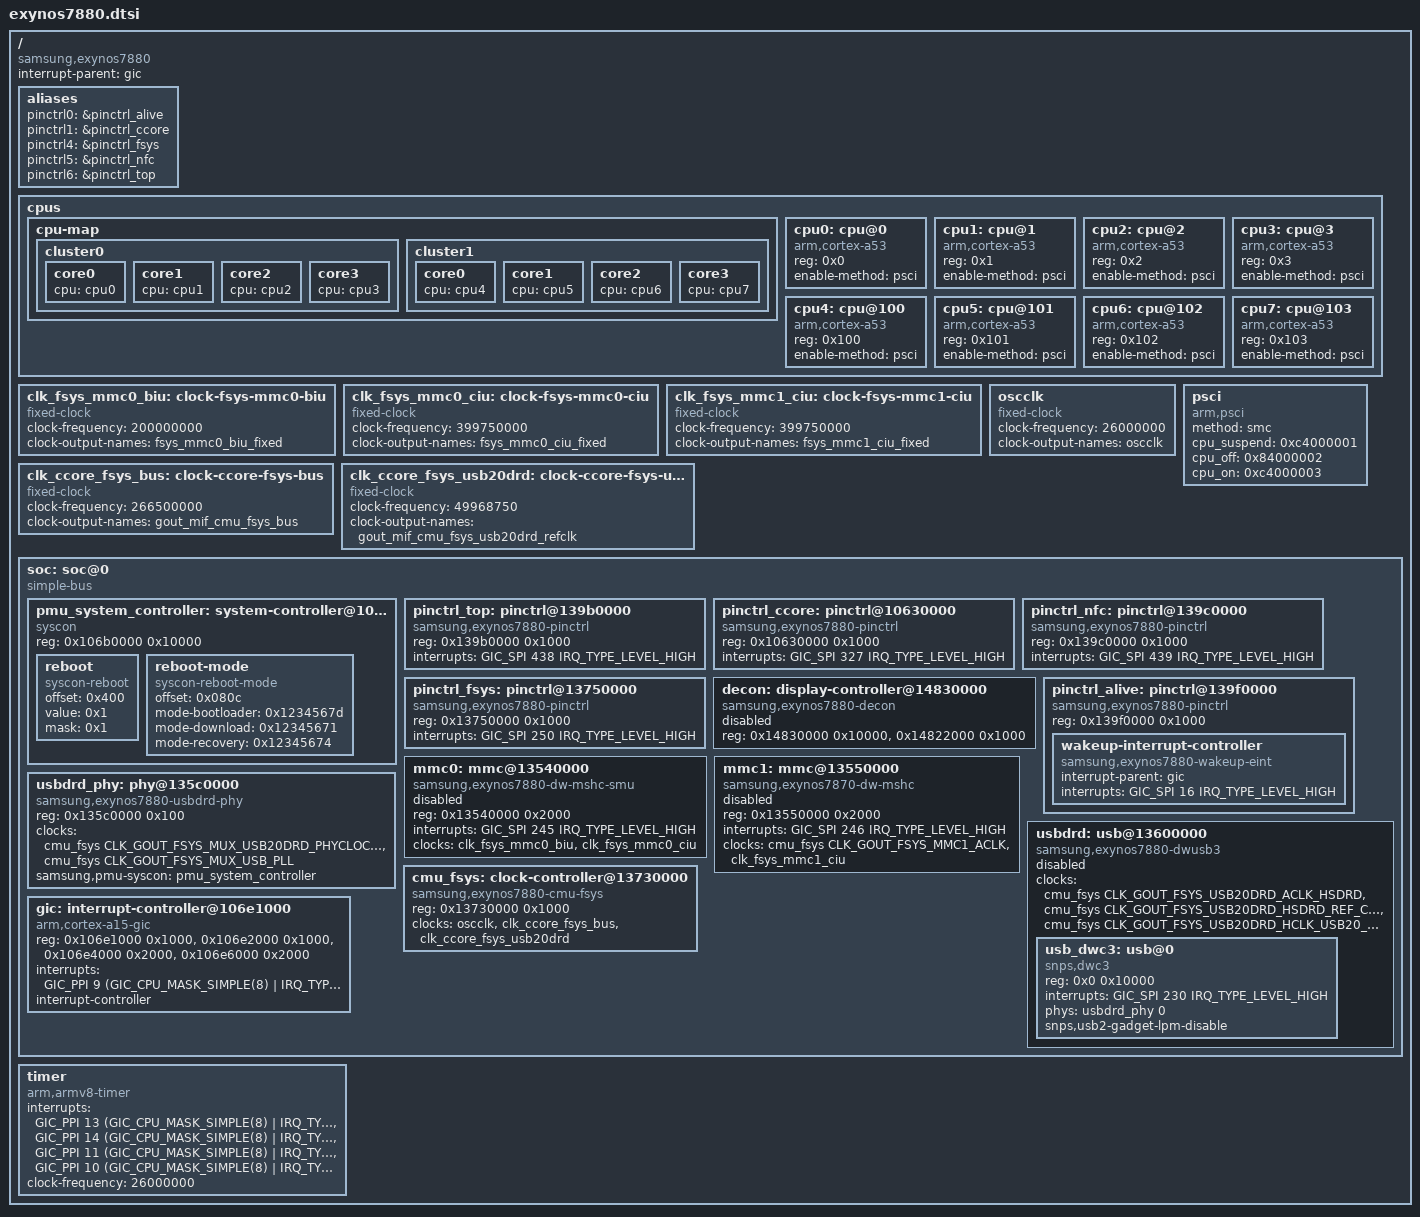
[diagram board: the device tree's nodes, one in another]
// SPDX-License-Identifier: GPL-2.0
/*
 * Samsung Exynos 7880 SoC device tree source
 *
 * M1: CPUs (PSCI), GIC, architected timer, PMU (reboot). M2: ALIVE pin
 * controller. M3: eMMC (fixed clocks). M4: CMU_FSYS (Exynos7870 driver,
 * identical register map), USB DRD PHY and DWC3 controller.
 *
 * Sources for every value:
 *  [D] Samsung universal7880 kernel, hybris-17.1: arch/arm64/boot/dts/exynos7880.dtsi
 *  [M] Linux v7.2 arch/arm64/boot/dts/exynos/exynos7870.dtsi (sibling SoC)
 *  [H] a5y17lte hardware readings, EVIDENCE.md sections 12
 *  [P] Samsung pwrcal S5E7880-cmusfr.h / -cmu.c / -pmusfr.h (same kernel)
 */

#include <dt-bindings/clock/samsung,exynos7870-cmu.h>
#include <dt-bindings/interrupt-controller/arm-gic.h>

/ {
	compatible = "samsung,exynos7880";
	#address-cells = <2>;
	#size-cells = <1>;

	interrupt-parent = <&gic>;

	aliases {
		/* index into exynos7880_pin_ctrl[] (Linux pinctrl-exynos-arm64.c) */
		pinctrl0 = &pinctrl_alive;
		pinctrl1 = &pinctrl_ccore;
		pinctrl4 = &pinctrl_fsys;
		pinctrl5 = &pinctrl_nfc;
		pinctrl6 = &pinctrl_top;
	};

	cpus {
		#address-cells = <1>;
		#size-cells = <0>;

		cpu-map {
			cluster0 {
				core0 { cpu = <&cpu0>; };
				core1 { cpu = <&cpu1>; };
				core2 { cpu = <&cpu2>; };
				core3 { cpu = <&cpu3>; };
			};

			cluster1 {
				core0 { cpu = <&cpu4>; };
				core1 { cpu = <&cpu5>; };
				core2 { cpu = <&cpu6>; };
				core3 { cpu = <&cpu7>; };
			};
		};

		/* [D] cpu@0..3, cpu@100..103, all cortex-a53, enable-method psci;
		 * [H] boot CPU MIDR 0x410fd034, MPIDR 0x80000000 */
		cpu0: cpu@0 {
			device_type = "cpu";
			compatible = "arm,cortex-a53";
			reg = <0x0>;
			enable-method = "psci";
		};

		cpu1: cpu@1 {
			device_type = "cpu";
			compatible = "arm,cortex-a53";
			reg = <0x1>;
			enable-method = "psci";
		};

		cpu2: cpu@2 {
			device_type = "cpu";
			compatible = "arm,cortex-a53";
			reg = <0x2>;
			enable-method = "psci";
		};

		cpu3: cpu@3 {
			device_type = "cpu";
			compatible = "arm,cortex-a53";
			reg = <0x3>;
			enable-method = "psci";
		};

		cpu4: cpu@100 {
			device_type = "cpu";
			compatible = "arm,cortex-a53";
			reg = <0x100>;
			enable-method = "psci";
		};

		cpu5: cpu@101 {
			device_type = "cpu";
			compatible = "arm,cortex-a53";
			reg = <0x101>;
			enable-method = "psci";
		};

		cpu6: cpu@102 {
			device_type = "cpu";
			compatible = "arm,cortex-a53";
			reg = <0x102>;
			enable-method = "psci";
		};

		cpu7: cpu@103 {
			device_type = "cpu";
			compatible = "arm,cortex-a53";
			reg = <0x103>;
			enable-method = "psci";
		};
	};

	/*
	 * TEMPORARY: there is no Exynos7880 clock driver yet, so the eMMC
	 * bus/card clocks are fixed clocks. S-Boot leaves them running.
	 * CIU measured on the phone (EVIDENCE.md 17b): CMU_CCORE MMC0 mux =
	 * BUS_PLL/2, div = 2, BUS_PLL = 26 MHz * 246 / 4 = 1599 MHz, so
	 * 1599 / 2 / 2 = 399.75 MHz. Replace with CMU clocks later.
	 */
	clk_fsys_mmc0_biu: clock-fsys-mmc0-biu {
		compatible = "fixed-clock";
		#clock-cells = <0>;
		clock-frequency = <200000000>;
		clock-output-names = "fsys_mmc0_biu_fixed";
	};

	clk_fsys_mmc0_ciu: clock-fsys-mmc0-ciu {
		compatible = "fixed-clock";
		#clock-cells = <0>;
		clock-frequency = <399750000>;
		clock-output-names = "fsys_mmc0_ciu_fixed";
	};

	/*
	 * mmc1 (SDIO, Wi-Fi): CIU clock from CMU_MIF CMU_FSYS_MMC1, which is not
	 * supported yet; same 399.75 MHz as the mmc0 stand-in (EVIDENCE 35: unverified
	 * for this block, S-Boot never uses mmc1).
	 */
	clk_fsys_mmc1_ciu: clock-fsys-mmc1-ciu {
		compatible = "fixed-clock";
		#clock-cells = <0>;
		clock-frequency = <399750000>;
		clock-output-names = "fsys_mmc1_ciu_fixed";
	};

	/* [D] 26 MHz crystal; [M] node name gives the "oscclk" clock name */
	oscclk: oscclk {
		compatible = "fixed-clock";
		#clock-cells = <0>;
		clock-frequency = <26000000>;
		clock-output-names = "oscclk";
	};

	/*
	 * TEMPORARY: the two CMU_FSYS inputs come from CMU_CCORE on Exynos7880
	 * ([P] CCORE_GATE_CLKCMU_FSYS_BUS / _USB20DRD_REFCLK), which has no
	 * Linux driver yet. The Exynos7870 CMU_FSYS driver looks its parents up
	 * by the CMU_MIF clock names, hence these output names. S-Boot leaves
	 * them running. Rates measured on the phone (EVIDENCE.md 18a):
	 * FSYS_BUS = BUS_PLL/2 / 3 = 266.5 MHz, USB20DRD = BUS_PLL/2 / 16.
	 */
	clk_ccore_fsys_bus: clock-ccore-fsys-bus {
		compatible = "fixed-clock";
		#clock-cells = <0>;
		clock-frequency = <266500000>;
		clock-output-names = "gout_mif_cmu_fsys_bus";
	};

	clk_ccore_fsys_usb20drd: clock-ccore-fsys-usb20drd {
		compatible = "fixed-clock";
		#clock-cells = <0>;
		clock-frequency = <49968750>;
		clock-output-names = "gout_mif_cmu_fsys_usb20drd_refclk";
	};

	/* [D] psci: method smc, cpu_suspend 0xC4000001 (same IDs as [M]) */
	psci {
		compatible = "arm,psci";
		method = "smc";
		cpu_suspend = <0xc4000001>;
		cpu_off = <0x84000002>;
		cpu_on = <0xc4000003>;
	};

	soc: soc@0 {
		compatible = "simple-bus";
		ranges = <0x0 0x0 0x0 0x20000000>;
		#address-cells = <1>;
		#size-cells = <1>;

		/*
		 * [D] system-controller@106B0000, 0x10000 long. Plain syscon for now
		 * (no exynos-pmu driver): used only for reset and reboot modes.
		 */
		pmu_system_controller: system-controller@106b0000 {
			compatible = "syscon", "simple-mfd";
			reg = <0x106b0000 0x10000>;

			/* Samsung exynos-reboot.c: EXYNOS_PMU_SWRESET (0x400) = 1;
			 * [H] confirmed: resets the phone (step 1b) */
			reboot {
				compatible = "syscon-reboot";
				offset = <0x400>;
				value = <0x1>;
				mask = <0x1>;
			};

			/* Samsung sec_ext.h: INFORM3 = 0x80C; sec_reboot.c:
			 * prefix 0x12345670 | 1 download, 4 recovery, 0xd bootloader
			 * (identical values in [M]) */
			reboot-mode {
				compatible = "syscon-reboot-mode";
				offset = <0x080c>;
				mode-bootloader = <0x1234567d>;
				mode-download = <0x12345671>;
				mode-recovery = <0x12345674>;
			};
		};

		/*
		 * [D] pinctrl_6: pinctrl@139B0000 (TOP), GPIO EINT on SPI 438;
		 * same address and interrupt as the Exynos7870 TOP controller.
		 */
		pinctrl_top: pinctrl@139b0000 {
			compatible = "samsung,exynos7880-pinctrl";
			reg = <0x139b0000 0x1000>;
			interrupts = <GIC_SPI 438 IRQ_TYPE_LEVEL_HIGH>;
		};

		/* [D] pinctrl_1: pinctrl@10630000 (CCORE: gpm0, the PMIC I2C pins), SPI 327 */
		pinctrl_ccore: pinctrl@10630000 {
			compatible = "samsung,exynos7880-pinctrl";
			reg = <0x10630000 0x1000>;
			interrupts = <GIC_SPI 327 IRQ_TYPE_LEVEL_HIGH>;
		};

		/*
		 * [D] pinctrl_5: pinctrl@139C0000 (NFC: gpc2, the touchscreen I2C pins),
		 * SPI 439. The vendor node also has the gate_pinctrl clock (clock 152);
		 * no CMU_PERI driver yet, so the bootloader's state is relied on.
		 */
		pinctrl_nfc: pinctrl@139c0000 {
			compatible = "samsung,exynos7880-pinctrl";
			reg = <0x139c0000 0x1000>;
			interrupts = <GIC_SPI 439 IRQ_TYPE_LEVEL_HIGH>;
		};

		/* [D] pinctrl_4: pinctrl@13750000 (FSYS: gpr0-gpr4, eMMC/SD pins), SPI 250 */
		pinctrl_fsys: pinctrl@13750000 {
			compatible = "samsung,exynos7880-pinctrl";
			reg = <0x13750000 0x1000>;
			interrupts = <GIC_SPI 250 IRQ_TYPE_LEVEL_HIGH>;
		};

		/*
		 * [D] decon_f@14830000 and its graphics DMA channel idma_g1@14822000, adopted from
		 * the bootloader (EVIDENCE 40): no clocks, power domain or IRQ are claimed, S-Boot's
		 * state is relied on like for the other display blocks.
		 */
		decon: display-controller@14830000 {
			compatible = "samsung,exynos7880-decon";
			reg = <0x14830000 0x10000>, <0x14822000 0x1000>;
			reg-names = "decon", "idma";
			status = "disabled";
		};

		/* [D] pinctrl_0: pinctrl@139F0000, wake-up EINT on SPI 16 */
		pinctrl_alive: pinctrl@139f0000 {
			compatible = "samsung,exynos7880-pinctrl";
			reg = <0x139f0000 0x1000>;

			wakeup-interrupt-controller {
				compatible = "samsung,exynos7880-wakeup-eint",
					     "samsung,exynos7-wakeup-eint";
				interrupt-parent = <&gic>;
				interrupts = <GIC_SPI 16 IRQ_TYPE_LEVEL_HIGH>;
			};
		};

		/*
		 * [D] dwmmc_0: dwmmc0@13540000, SPI 245; same block as Exynos7870
		 * in the Samsung kernel (same driver, interrupt, clock IDs).
		 */
		mmc0: mmc@13540000 {
			compatible = "samsung,exynos7880-dw-mshc-smu",
				     "samsung,exynos7870-dw-mshc-smu";
			reg = <0x13540000 0x2000>;
			interrupts = <GIC_SPI 245 IRQ_TYPE_LEVEL_HIGH>;
			#address-cells = <1>;
			#size-cells = <0>;

			clock-names = "biu", "ciu";
			clocks = <&clk_fsys_mmc0_biu>, <&clk_fsys_mmc0_ciu>;

			status = "disabled";
		};

		/*
		 * [D] dwmmc_1: dwmmc1@13550000, SPI 246 (SDIO, QCA9377 Wi-Fi). BIU gate
		 * from CMU_FSYS (MMC1_ACLK, the register map of the 7870 driver); CIU fixed.
		 */
		mmc1: mmc@13550000 {
			compatible = "samsung,exynos7870-dw-mshc";
			reg = <0x13550000 0x2000>;
			interrupts = <GIC_SPI 246 IRQ_TYPE_LEVEL_HIGH>;
			#address-cells = <1>;
			#size-cells = <0>;

			clock-names = "biu", "ciu";
			clocks = <&cmu_fsys CLK_GOUT_FSYS_MMC1_ACLK>, <&clk_fsys_mmc1_ciu>;

			status = "disabled";
		};

		/*
		 * [D] usbdrd_phy: usbphy@135c0000, "samsung,exynos7870-usbdrd-phy"
		 * with the PMU syscon; [P] PMU_USBDEV_PHY_CONTROL = PMU + 0x704,
		 * the same offset the Exynos7870 PHY driver uses.
		 */
		usbdrd_phy: phy@135c0000 {
			compatible = "samsung,exynos7880-usbdrd-phy",
				     "samsung,exynos7870-usbdrd-phy";
			reg = <0x135c0000 0x100>;
			#phy-cells = <1>;

			clock-names = "phy", "ref";
			clocks = <&cmu_fsys CLK_GOUT_FSYS_MUX_USB20DRD_PHYCLOCK_USER>,
				 <&cmu_fsys CLK_GOUT_FSYS_MUX_USB_PLL>;

			samsung,pmu-syscon = <&pmu_system_controller>;
		};

		/*
		 * [D] udc: usb@13600000, "samsung,exynos7870-dwusb2", DWC3 at
		 * SPI 230, same clocks as Exynos7870.
		 */
		usbdrd: usb@13600000 {
			compatible = "samsung,exynos7880-dwusb3",
				     "samsung,exynos7870-dwusb3";
			ranges = <0x0 0x13600000 0x10000>;
			#address-cells = <1>;
			#size-cells = <1>;

			clock-names = "bus_early", "ref", "ctrl";
			clocks = <&cmu_fsys CLK_GOUT_FSYS_USB20DRD_ACLK_HSDRD>,
				 <&cmu_fsys CLK_GOUT_FSYS_USB20DRD_HSDRD_REF_CLK>,
				 <&cmu_fsys CLK_GOUT_FSYS_USB20DRD_HCLK_USB20_CTRL>;

			status = "disabled";

			usb_dwc3: usb@0 {
				compatible = "snps,dwc3";
				reg = <0x0 0x10000>;
				interrupts = <GIC_SPI 230 IRQ_TYPE_LEVEL_HIGH>;

				phy-names = "usb2-phy";
				phys = <&usbdrd_phy 0>;

				snps,usb2-gadget-lpm-disable;
			};
		};

		/*
		 * [P] CMU_FSYS @ 0x13730000: all 32 Exynos7870 registers at the
		 * same offsets and bits (7880 adds one gate register), USB_PLL is
		 * the same pll1418x. Inputs: OSCCLK, CMU_CCORE FSYS_BUS/USB20DRD.
		 */
		cmu_fsys: clock-controller@13730000 {
			compatible = "samsung,exynos7880-cmu-fsys",
				     "samsung,exynos7870-cmu-fsys";
			reg = <0x13730000 0x1000>;
			#clock-cells = <1>;

			clock-names = "oscclk", "bus", "usb20drd";
			clocks = <&oscclk>, <&clk_ccore_fsys_bus>,
				 <&clk_ccore_fsys_usb20drd>;
		};

		/* [D] gic: interrupt-controller@106E1000, 4 regions, PPI 9 */
		gic: interrupt-controller@106e1000 {
			compatible = "arm,cortex-a15-gic";
			reg = <0x106e1000 0x1000>,
			      <0x106e2000 0x1000>,
			      <0x106e4000 0x2000>,
			      <0x106e6000 0x2000>;
			interrupts = <GIC_PPI 9 (GIC_CPU_MASK_SIMPLE(8) |
						 IRQ_TYPE_LEVEL_HIGH)>;
			interrupt-controller;
			#address-cells = <0>;
			#interrupt-cells = <3>;
		};
	};

	/* [D] PPIs 13 14 11 10; [M] same; [H] CNTFRQ_EL0 = 0 so the
	 * frequency must come from here (26 MHz, [D] and [M]) */
	timer {
		compatible = "arm,armv8-timer";
		interrupts = <GIC_PPI 13 (GIC_CPU_MASK_SIMPLE(8) | IRQ_TYPE_LEVEL_LOW)>,
			     <GIC_PPI 14 (GIC_CPU_MASK_SIMPLE(8) | IRQ_TYPE_LEVEL_LOW)>,
			     <GIC_PPI 11 (GIC_CPU_MASK_SIMPLE(8) | IRQ_TYPE_LEVEL_LOW)>,
			     <GIC_PPI 10 (GIC_CPU_MASK_SIMPLE(8) | IRQ_TYPE_LEVEL_LOW)>;
		clock-frequency = <26000000>;
	};
};

#include "exynos7880-pinctrl.dtsi"
